# platform_designer_hps_system_hps_0_hps register map
Vendor: default_vendor.com; File version: 0.0
Registers are 32-bit, read-write, reset 0x0 unless marked. A register's access mark holds for its fields unless they carry their own. Offsets are from the block's base; [hi:lo] are bit positions; lines under a group give offsets from that group; {n}, {i} and the like mark numbered series.

## emac0 (part 2 of 5) — Registers in the EMAC module.
Base 0xFF700000
Same registers: emac1 0xFF702000
0x44 gmacgrp_MAC_Address0_Low reset 0xFFFFFFFF — The MAC Address0 Low register holds the lower 32 bits of the first 6-byte MAC address of the station.
  [31:0] addrlo — This field contains the lower 32 bits of the first 6-byte MAC address. This is used by the MAC for filtering the received frames and inserting the MAC address in the Transmit Flow Control (PAUSE) Frames.
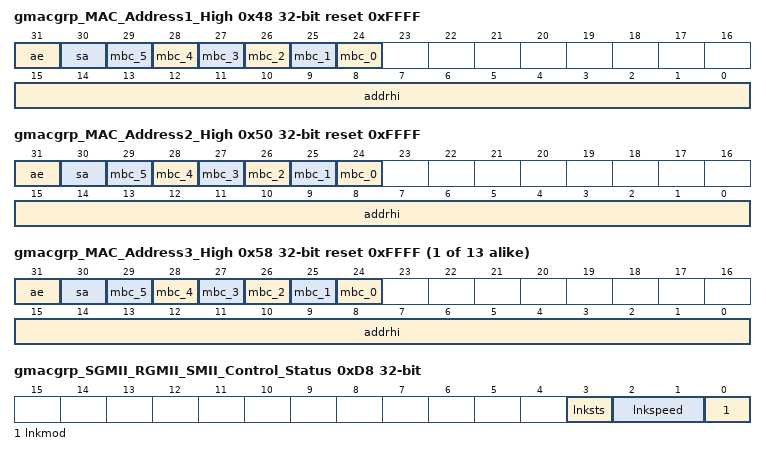
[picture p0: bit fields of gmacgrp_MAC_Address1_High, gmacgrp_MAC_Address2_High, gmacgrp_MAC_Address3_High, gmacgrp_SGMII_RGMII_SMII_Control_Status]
0x48 gmacgrp_MAC_Address1_High reset 0xFFFF — The MAC Address1 High register holds the upper 16 bits of the 2nd 6-byte MAC address of the station. Because the MAC address registers are configured to be double-synchronized to the (G)MII clock domains, the synchronization is triggered only when bits[31:24] (in little-endian mode) or Bits[7:0] (in big-endian mode) of the MAC Address1 Low Register are written. For proper synchronization updates, the consecutive writes to this Address Low Register should be performed after at least four clock cycles in the destination clock domain. Note that all MAC Address High registers (except MAC Address0 High) have the same format.
  [31] ae — When this bit is enabled, the address filter block uses the 2nd MAC address for perfect filtering. When this bit is disabled, the address filter block ignores the address for filtering.
    0=disabled; 1=enabled
  [30] sa — When this bit is enabled, the MAC Address1[47:0] is used to compare with the SA fields of the received frame. When this bit is disabled, the MAC Address1[47:0] is used to compare with the DA fields of the received frame.
    0=disabled; 1=enabled
  [n+24] mbc_{n} (n=0..5) — This array of bits are mask control bits for comparison of each of the MAC Address bytes. When masked, the MAC does not compare the corresponding byte of received DA or SA with the contents of MAC Address1 high and low registers. Each bit controls the masking of the bytes. You can filter a group of addresses (known as group address filtering) by masking one or more bytes of the address. The array index corresponds to the byte (e.g. index 0 is for bits 7:0).
    0=unmasked; 1=masked
  [15:0] addrhi — This field contains the upper 16 bits (47:32) of the 2nd 6-byte MAC address.
0x4C gmacgrp_MAC_Address1_Low reset 0xFFFFFFFF — The MAC Address1 Low register holds the lower 32 bits of the 2nd 6-byte MAC address of the station. Note that all MAC Address Low registers (except MAC Address0 Low) have the same format.
  [31:0] addrlo — This field contains the lower 32 bits of the 2nd 6-byte MAC address. The content of this field is undefined until loaded by software after the initialization process.
0x50 gmacgrp_MAC_Address2_High reset 0xFFFF — The MAC Address2 High register holds the upper 16 bits of the 3rd 6-byte MAC address of the station. Because the MAC address registers are configured to be double-synchronized to the (G)MII clock domains, the synchronization is triggered only when bits[31:24] (in little-endian mode) or Bits[7:0] (in big-endian mode) of the MAC Address2 Low Register are written. For proper synchronization updates, the consecutive writes to this Address Low Register should be performed after at least four clock cycles in the destination clock domain. Note that all MAC Address High registers (except MAC Address0 High) have the same format.
  [31] ae — When this bit is enabled, the address filter block uses the 3rd MAC address for perfect filtering. When this bit is disabled, the address filter block ignores the address for filtering.
    0=disabled; 1=enabled
  [30] sa — When this bit is enabled, the MAC Address2[47:0] is used to compare with the SA fields of the received frame. When this bit is disabled, the MAC Address2[47:0] is used to compare with the DA fields of the received frame.
    0=disabled; 1=enabled
  [n+24] mbc_{n} (n=0..5) — This array of bits are mask control bits for comparison of each of the MAC Address bytes. When masked, the MAC does not compare the corresponding byte of received DA or SA with the contents of MAC Address2 high and low registers. Each bit controls the masking of the bytes. You can filter a group of addresses (known as group address filtering) by masking one or more bytes of the address. The array index corresponds to the byte (e.g. index 0 is for bits 7:0).
    0=unmasked; 1=masked
  [15:0] addrhi — This field contains the upper 16 bits (47:32) of the 3rd 6-byte MAC address.
0x54 gmacgrp_MAC_Address2_Low reset 0xFFFFFFFF — The MAC Address2 Low register holds the lower 32 bits of the 3rd 6-byte MAC address of the station. Note that all MAC Address Low registers (except MAC Address0 Low) have the same format.
  [31:0] addrlo — This field contains the lower 32 bits of the 3rd 6-byte MAC address. The content of this field is undefined until loaded by software after the initialization process.
{0x40+8i} gmacgrp_MAC_Address{i}_High reset 0xFFFF (i=3..15) — The MAC Address{i} High register holds the upper 16 bits of the {i+1}th 6-byte MAC address of the station. Because the MAC address registers are configured to be double-synchronized to the (G)MII clock domains, the synchronization is triggered only when bits[31:24] (in little-endian mode) or Bits[7:0] (in big-endian mode) of the MAC Address{i} Low Register are written. For proper synchronization updates, the consecutive writes to this Address Low Register should be performed after at least four clock cycles in the destination clock domain. Note that all MAC Address High registers (except MAC Address0 High) have the same format.
  [31] ae — When this bit is enabled, the address filter block uses the {i+1}th MAC address for perfect filtering. When this bit is disabled, the address filter block ignores the address for filtering.
    0=disabled; 1=enabled
  [30] sa — When this bit is enabled, the MAC Address{i}[47:0] is used to compare with the SA fields of the received frame. When this bit is disabled, the MAC Address{i}[47:0] is used to compare with the DA fields of the received frame.
    0=disabled; 1=enabled
  [n+24] mbc_{n} (n=0..5) — This array of bits are mask control bits for comparison of each of the MAC Address bytes. When masked, the MAC does not compare the corresponding byte of received DA or SA with the contents of MAC Address{i} high and low registers. Each bit controls the masking of the bytes. You can filter a group of addresses (known as group address filtering) by masking one or more bytes of the address. The array index corresponds to the byte (e.g. index 0 is for bits 7:0).
    0=unmasked; 1=masked
  [15:0] addrhi — This field contains the upper 16 bits (47:32) of the {i+1}th 6-byte MAC address.
{0x44+8i} gmacgrp_MAC_Address{i}_Low reset 0xFFFFFFFF (i=3..15) — The MAC Address{i} Low register holds the lower 32 bits of the {i+1}th 6-byte MAC address of the station. Note that all MAC Address Low registers (except MAC Address0 Low) have the same format.
  [31:0] addrlo — This field contains the lower 32 bits of the {i+1}th 6-byte MAC address. The content of this field is undefined until loaded by software after the initialization process.
0xD8 gmacgrp_SGMII_RGMII_SMII_Control_Status ro — The SGMII/RGMII/SMII Status register indicates the status signals received by the RGMII interface (selected at reset) from the PHY.
  [3] lnksts — This bit indicates whether the link is up (1'b1) or down (1'b0).
    0=linkdown; 1=linkup
  [2:1] lnkspeed — This bit indicates the current speed of the link. Bit 2 is reserved when the MAC is configured for the SMII PHY interface.
    0=speed2point5MHz; 1=speed25MHz; 2=speed125MHz
  [0] lnkmod — This bit indicates the current mode of operation of the link
    0=halfdup; 1=fulldup
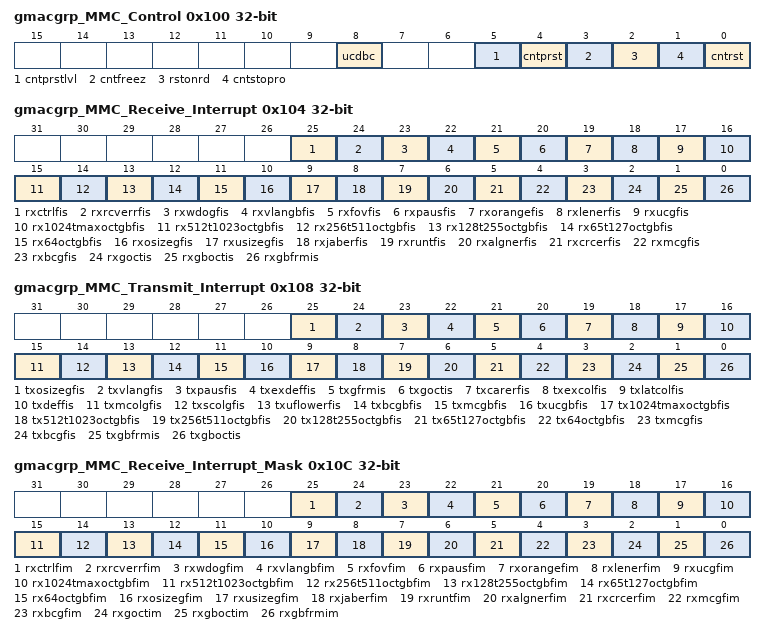
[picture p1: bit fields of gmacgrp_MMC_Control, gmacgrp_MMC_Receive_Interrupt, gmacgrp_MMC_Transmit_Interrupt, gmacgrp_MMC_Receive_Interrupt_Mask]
0x100 gmacgrp_MMC_Control — The MMC Control register establishes the operating mode of the management counters. Note: The bit 0 (Counters Reset) has higher priority than bit 4 (Counter Preset). Therefore, when the Software tries to set both bits in the same write cycle, all counters are cleared and the bit 4 is not set.
  [8] ucdbc — When set, this bit enables MAC to update all the related MMC Counters for Broadcast frames dropped due to setting of DBF bit (Disable Broadcast Frames) of MAC Filter Register at offset 0x0004. When reset, MMC Counters are not updated for dropped Broadcast frames.
  [5] cntprstlvl — When low and bit 4 is set, all MMC counters get preset to almost-half value. All octet counters get preset to 0x7FFF_F800 (half - 2KBytes) and all frame-counters gets preset to 0x7FFF_FFF0 (half - 16). When this bit is high and bit 4 is set, all MMC counters get preset to almost-full value. All octet counters get preset to 0xFFFF_F800 (full - 2KBytes) and all frame-counters gets preset to 0xFFFF_FFF0 (full - 16). For 16-bit counters, the almost-half preset values are 0x7800 and 0x7FF0 for the respective octet and frame counters. Similarly, the almost-full preset values for the 16-bit counters are 0xF800 and 0xFFF0.
    0=almosthalf; 1=almostfull
  [4] cntprst — When this bit is set, all counters are initialized or preset to almost full or almost half according to bit 5. This bit is cleared automatically after 1 clock cycle. This bit, along with bit 5, is useful for debugging and testing the assertion of interrupts because of MMC counter becoming half-full or full.
    0=disabled; 1=enabled
  [3] cntfreez — When this bit is set, it freezes all MMC counters to their current value. Until this bit is reset to 0, no MMC counter is updated because of any transmitted or received frame. If any MMC counter is read with the Reset on Read bit set, then that counter is also cleared in this mode.
    0=disabled; 1=enabled
  [2] rstonrd — When this bit is set, the MMC counters are reset to zero after Read (self-clearing after reset). The counters are cleared when the least significant byte lane (bits[7:0]) is read.
    0=disabled; 1=enabled
  [1] cntstopro — When this bit is set, after reaching maximum value, the counter does not roll over to zero.
    0=disabled; 1=enabled
  [0] cntrst — When this bit is set, all counters are reset. This bit is cleared automatically after one clock cycle.
    0=disabled; 1=enabled
0x104 gmacgrp_MMC_Receive_Interrupt ro — The MMC Receive Interrupt register maintains the interrupts that are generated when the following happens: * Receive statistic counters reach half of their maximum values (0x8000_0000 for 32-bit counter and 0x8000 for 16-bit counter). * Receive statistic counters cross their maximum values (0xFFFF_FFFF for 32-bit counter and 0xFFFF for 16-bit counter). When the Counter Stop Rollover is set, then interrupts are set but the counter remains at all-ones. The MMC Receive Interrupt register is a 32-bit wide register. An interrupt bit is cleared when the respective MMC counter that caused the interrupt is read. The least significant byte lane (Bits[7:0]) of the respective counter must be read in order to clear the interrupt bit.
  [25] rxctrlfis — This bit is set when the rxctrlframes_g counter reaches half of the maximum value or the maximum value.
  [24] rxrcverrfis — This bit is set when the rxrcverror counter reaches half of the maximum value or the maximum value.
  [23] rxwdogfis — This bit is set when the rxwatchdogerror counter reaches half of the maximum value or the maximum value.
    0=inactive; 1=active
  [22] rxvlangbfis — This bit is set when the rxvlanframes_gb counter reaches half of the maximum value or the maximum value.
    0=inactive; 1=active
  [21] rxfovfis — This bit is set when the rxfifooverflow counter reaches half of the maximum value or the maximum value.
    0=inactive; 1=active
  [20] rxpausfis — This bit is set when the rxpauseframe counter reaches half of the maximum value or the maximum value.
    0=inactive; 1=active
  [19] rxorangefis — This bit is set when the rxoutofrangetype counter reaches half of the maximum value or the maximum value.
    0=inactive; 1=active
  [18] rxlenerfis — This bit is set when the rxlengtherror counter reaches half of the maximum value or the maximum value.
    0=inactive; 1=active
  [17] rxucgfis — This bit is set when the rxunicastframes_gb counter reaches half of the maximum value or the maximum value.
    0=inactive; 1=active
  [16] rx1024tmaxoctgbfis — This bit is set when the rx1024tomaxoctets_gb counter reaches half of the maximum value or the maximum value.
    0=inactive; 1=active
  [15] rx512t1023octgbfis — This bit is set when the rx512to1023octets_gb counter reaches half of the maximum value or the maximum value.
    0=inactive; 1=active
  [14] rx256t511octgbfis — This bit is set when the rx256to511octets_gb counter reaches half of the maximum value or the maximum value.
    0=inactive; 1=active
  [13] rx128t255octgbfis — This bit is set when the rx128to255octets_gb counter reaches half of the maximum value or the maximum value.
    0=inactive; 1=active
  [12] rx65t127octgbfis — This is set when the rx65to127octets_gb counter reaches half of the maximum value or the maximum value.
    0=inactive; 1=active
  [11] rx64octgbfis — This bit is set when the rx64octets_gb counter reaches half of the maximum value or the maximum value.
    0=inactive; 1=active
  [10] rxosizegfis — This bit is set when the rxoversize_g counter reaches half of the maximum value or the maximum value.
    0=inactive; 1=active
  [9] rxusizegfis — This bit is set when the rxundersize_g counter reaches half of the maximum value or the maximum value.
    0=inactive; 1=active
  [8] rxjaberfis — This bit is set when the rxjabbererror counter reaches half of the maximum value or the maximum value.
    0=inactive; 1=active
  [7] rxruntfis — This bit is set when the rxrunterror counter reaches half of the maximum value or the maximum value.
    0=inactive; 1=active
  [6] rxalgnerfis — This bit is set when the rxalignmenterror counter reaches half of the maximum value or the maximum value.
    0=inactive; 1=active
  [5] rxcrcerfis — This bit is set when the rxcrcerror counter reaches half of the maximum value or the maximum value.
    0=inactive; 1=active
  [4] rxmcgfis — This bit is set when the rxmulticastframes_g counter reaches half of the maximum value or the maximum value.
    0=inactive; 1=active
  [3] rxbcgfis — This bit is set when the rxbroadcastframes_g counter reaches half of the maximum value or the maximum value.
  [2] rxgoctis — This bit is set when the rxoctetcount_g counter reaches half of the maximum value or the maximum value.
    0=inactive; 1=active
  [1] rxgboctis — This bit is set when the rxoctetcount_bg counter reaches half of the maximum value or the maximum value.
    0=inactive; 1=active
  [0] rxgbfrmis — This bit is set when the rxframecount_bg counter reaches half of the maximum value or the maximum value.
    0=almosthalf; 1=almostfull
0x108 gmacgrp_MMC_Transmit_Interrupt ro — The MMC Transmit Interrupt register maintains the interrupts generated when transmit statistic counters reach half of their maximum values (0x8000_0000 for 32-bit counter and 0x8000 for 16-bit counter), and the maximum values (0xFFFF_FFFF for 32-bit counter and 0xFFFF for 16-bit counter). When Counter Stop Rollover is set, then interrupts are set but the counter remains at all-ones. The MMC Transmit Interrupt register is a 32-bit wide register. An interrupt bit is cleared when the respective MMC counter that caused the interrupt is read. The least significant byte lane (Bits[7:0]) of the respective counter must be read in order to clear the interrupt bit.
  [25] txosizegfis — This bit is set when the txoversize_g counter reaches half of the maximum value or the maximum value.
  [24] txvlangfis — This bit is set when the txvlanframes_g counter reaches half of the maximum value or the maximum value.
    0=disabled; 1=enabled
  [23] txpausfis — This bit is set when the txpauseframeserror counter reaches half of the maximum value or the maximum value.
    0=disabled; 1=enabled
  [22] txexdeffis — This bit is set when the txexcessdef counter reaches half of the maximum value or the maximum value.
    0=disabled; 1=enabled
  [21] txgfrmis — This bit is set when the txframecount_g counter reaches half of the maximum value or the maximum value.
    0=disabled; 1=enabled
  [20] txgoctis — This bit is set when the txoctetcount_g counter reaches half of the maximum value or the maximum value.
    0=disabled; 1=enabled
  [19] txcarerfis — This bit is set when the txcarriererror counter reaches half of the maximum value or the maximum value.
    0=disabled; 1=enabled
  [18] txexcolfis — This bit is set when the txexcesscol counter reaches half of the maximum value or the maximum value.
    0=disabled; 1=enabled
  [17] txlatcolfis — This bit is set when the txlatecol counter reaches half of the maximum value or the maximum value.
    0=disabled; 1=enabled
  [16] txdeffis — This bit is set when the txdeferred counter reaches half of the maximum value or the maximum value.
    0=disabled; 1=enabled
  [15] txmcolgfis — This bit is set when the txmulticol_g counter reaches half of the maximum value or the maximum value.
    0=disabled; 1=enabled
  [14] txscolgfis — This bit is set when the txsinglecol_g counter reaches half of the maximum value or the maximum value.
    0=disabled; 1=enabled
  [13] txuflowerfis — This bit is set when the txunderflowerror counter reaches half of the maximum value or the maximum value.
    0=disabled; 1=enabled
  [12] txbcgbfis — This bit is set when the txbroadcastframes_gb counter reaches half of the maximum value or the maximum value.
    0=disabled; 1=enabled
  [11] txmcgbfis — This bit is set when the txmulticastframes_gb counter reaches half of the maximum value or the maximum value.
    0=inactive; 1=active
  [10] txucgbfis — This bit is set when the txunicastframes_gb counter reaches half of the maximum value or the maximum value.
    0=inactive; 1=active
  [9] tx1024tmaxoctgbfis — This bit is set when the tx1024tomaxoctets_gb counter reaches half of the maximum value or the maximum value.
    0=inactive; 1=active
  [8] tx512t1023octgbfis — This bit is set when the tx512to1023octets_gb counter reaches half of the maximum value or the maximum value.
    0=inactive; 1=active
  [7] tx256t511octgbfis — This bit is set when the tx256to511octets_gb counter reaches half of the maximum value or the maximum value.
    0=inactive; 1=active
  [6] tx128t255octgbfis — This bit is set when the tx128to255octets_gb counter reaches half of the maximum value or the maximum value.
    0=inactive; 1=active
  [5] tx65t127octgbfis — This bit is set when the tx65to127octets_gb counter reaches half of the maximum value or the maximum value.
    0=inactive; 1=active
  [4] tx64octgbfis — This bit is set when the tx64octets_gb counter reaches half of the maximum value or the maximum value.
    0=disabled; 1=enabled
  [3] txmcgfis — This bit is set when the txmulticastframes_g counter reaches half of the maximum value or the maximum value.
    0=inactive; 1=active
  [2] txbcgfis — This bit is set when the txbroadcastframes_g counter reaches half of the maximum value or the maximum value.
    0=inactive; 1=active
  [1] txgbfrmis — This bit is set when the txframecount_gb counter reaches half of the maximum value or the maximum value.
    0=inactive; 1=active
  [0] txgboctis — This bit is set when the txoctetcount_gb counter reaches half of the maximum value or the maximum value.
    0=inactive; 1=active
0x10C gmacgrp_MMC_Receive_Interrupt_Mask — The MMC Receive Interrupt Mask register maintains the masks for the interrupts generated when the receive statistic counters reach half of their maximum value, or maximum value. This register is 32-bits wide.
  [all] fields
    0=nomaskintr; 1=maskintr
  [25] rxctrlfim — Setting this bit masks the interrupt when the rxctrlframes counter reaches half the maximum value, and also when it reaches the maximum value.
  [24] rxrcverrfim — Setting this bit masks the interrupt when the rxrcverror error counter reaches half the maximum value, and also when it reaches the maximum value.
  [23] rxwdogfim — Setting this bit masks the interrupt when the rxwatchdog counter reaches half of the maximum value or the maximum value.
  [22] rxvlangbfim — Setting this bit masks the interrupt when the rxvlanframes_gb counter reaches half of the maximum value or the maximum value.
  [21] rxfovfim — Setting this bit masks the interrupt when the rxfifooverflow counter reaches half of the maximum value or the maximum value.
  [20] rxpausfim — Setting this bit masks the interrupt when the rxpauseframes counter reaches half of the maximum value or the maximum value.
  [19] rxorangefim — Setting this bit masks the interrupt when the rxoutofrangetype counter reaches half of the maximum value or the maximum value.
  [18] rxlenerfim — Setting this bit masks the interrupt when the rxlengtherror counter reaches half of the maximum value or the maximum value.
  [17] rxucgfim — Setting this bit masks the interrupt when the rxunicastframes_g counter reaches half of the maximum value or the maximum value.
  [16] rx1024tmaxoctgbfim — Setting this bit masks the interrupt when the rx1024tomaxoctets_gb counter reaches half of the maximum value or the maximum value.
  [15] rx512t1023octgbfim — Setting this bit masks the interrupt when the rx512to1023octets_gb counter reaches half of the maximum value or the maximum value.
  [14] rx256t511octgbfim — Setting this bit masks the interrupt when the rx256to511octets_gb counter reaches half of the maximum value or the maximum value.
  [13] rx128t255octgbfim — Setting this bit masks the interrupt when the rx128to255octets_gb counter reaches half of the maximum value or the maximum value.
  [12] rx65t127octgbfim — Setting this bit masks the interrupt when the rx65to127octets_gb counter reaches half of the maximum value or the maximum value.
  [11] rx64octgbfim — Setting this bit masks the interrupt when the rx64octets_gb counter reaches half of the maximum value or the maximum value.
  [10] rxosizegfim — Setting this bit masks the interrupt when the rxoversize_g counter reaches half of the maximum value or the maximum value.
  [9] rxusizegfim — Setting this bit masks the interrupt when the rxundersize_g counter reaches half of the maximum value or the maximum value.
  [8] rxjaberfim — Setting this bit masks the interrupt when the rxjabbererror counter reaches half of the maximum value or the maximum value.
  [7] rxruntfim — Setting this bit masks the interrupt when the rxrunterror counter reaches half of the maximum value or the maximum value.
  [6] rxalgnerfim — Setting this bit masks the interrupt when the rxalignmenterror counter reaches half of the maximum value or the maximum value.
  [5] rxcrcerfim — Setting this bit masks the interrupt when the rxcrcerror counter reaches half of the maximum value or the maximum value.
  [4] rxmcgfim — Setting this bit masks the interrupt when the rxmulticastframes_g counter reaches half of the maximum value or the maximum value.
  [3] rxbcgfim — Setting this bit masks the interrupt when the rxbroadcastframes_g counter reaches half of the maximum value or the maximum value.
  [2] rxgoctim — Setting this bit masks the interrupt when the rxoctetcount_g counter reaches half of the maximum value or the maximum value.
  [1] rxgboctim — Setting this bit masks the interrupt when the rxoctetcount_gb counter reaches half of the maximum value or the maximum value.
  [0] rxgbfrmim — Setting this bit masks the interrupt when the rxframecount_gb counter reaches half of the maximum value or the maximum value.
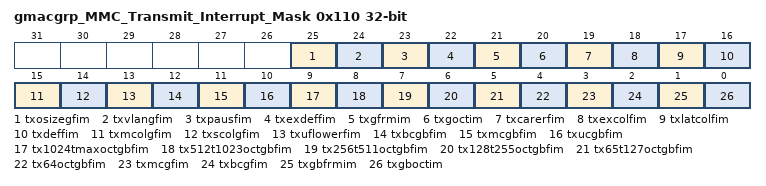
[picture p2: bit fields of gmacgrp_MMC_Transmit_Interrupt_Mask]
0x110 gmacgrp_MMC_Transmit_Interrupt_Mask — The MMC Transmit Interrupt Mask register maintains the masks for the interrupts generated when the transmit statistic counters reach half of their maximum value or maximum value. This register is 32-bits wide.
  [all] fields
    0=nomaskintr; 1=maskintr
  [25] txosizegfim — Setting this bit masks the interrupt when the txoversize_g counter reaches half of the maximum value or the maximum value.
  [24] txvlangfim — Setting this bit masks the interrupt when the txvlanframes_g counter reaches half of the maximum value or the maximum value.
  [23] txpausfim — Setting this bit masks the interrupt when the txpauseframes counter reaches half of the maximum value or the maximum value.
  [22] txexdeffim — Setting this bit masks the interrupt when the txexcessdef counter reaches half of the maximum value or the maximum value.
  [21] txgfrmim — Setting this bit masks the interrupt when the txframecount_g counter reaches half of the maximum value or the maximum value.
  [20] txgoctim — Setting this bit masks the interrupt when the txoctetcount_g counter reaches half of the maximum value or the maximum value.
  [19] txcarerfim — Setting this bit masks the interrupt when the txcarriererror counter reaches half of the maximum value or the maximum value.
  [18] txexcolfim — Setting this bit masks the interrupt when the txexcesscol counter reaches half of the maximum value or the maximum value.
  [17] txlatcolfim — Setting this bit masks the interrupt when the txlatecol counter reaches half of the maximum value or the maximum value.
  [16] txdeffim — Setting this bit masks the interrupt when the txdeferred counter reaches half of the maximum value or the maximum value.
  [15] txmcolgfim — Setting this bit masks the interrupt when the txmulticol_g counter reaches half of the maximum value or the maximum value.
  [14] txscolgfim — Setting this bit masks the interrupt when the txsinglecol_g counter reaches half of the maximum value or the maximum value.
  [13] txuflowerfim — Setting this bit masks the interrupt when the txunderflowerror counter reaches half of the maximum value or the maximum value.
  [12] txbcgbfim — Setting this bit masks the interrupt when the txbroadcastframes_gb counter reaches half of the maximum value or the maximum value.
  [11] txmcgbfim — Setting this bit masks the interrupt when the txmulticastframes_gb counter reaches half of the maximum value or the maximum value.
  [10] txucgbfim — Setting this bit masks the interrupt when the txunicastframes_gb counter reaches half of the maximum value or the maximum value.
  [9] tx1024tmaxoctgbfim — Setting this bit masks the interrupt when the tx1024tomaxoctets_gb counter reaches half of the maximum value or the maximum value.
  [8] tx512t1023octgbfim — Setting this bit masks the interrupt when the tx512to1023octets_gb counter reaches half of the maximum value or the maximum value.
  [7] tx256t511octgbfim — Setting this bit masks the interrupt when the tx256to511octets_gb counter reaches half of the maximum value or the maximum value.
  [6] tx128t255octgbfim — Setting this bit masks the interrupt when the tx128to255octets_gb counter reaches half of the maximum value or the maximum value.
  [5] tx65t127octgbfim — Setting this bit masks the interrupt when the tx65to127octets_gb counter reaches half of the maximum value or the maximum value.
  [4] tx64octgbfim — Setting this bit masks the interrupt when the tx64octets_gb counter reaches half of the maximum value or the maximum value.
  [3] txmcgfim — Setting this bit masks the interrupt when the txmulticastframes_g counter reaches half of the maximum value or the maximum value.
  [2] txbcgfim — Setting this bit masks the interrupt when the txbroadcastframes_g counter reaches half of the maximum value or the maximum value.
  [1] txgbfrmim — Setting this bit masks the interrupt when the txframecount_gb counter reaches half of the maximum value or the maximum value.
  [0] txgboctim — Setting this bit masks the interrupt when the txoctetcount_gb counter reaches half of the maximum value or the maximum value.
0x114 gmacgrp_txoctetcount_gb ro — Number of bytes transmitted, exclusive of preamble and retried bytes, in good and bad frames
  [31:0] cnt
0x118 gmacgrp_txframecount_gb ro — Number of good and bad frames transmitted, exclusive of retried frames
  [31:0] cnt
0x11C gmacgrp_txbroadcastframes_g ro — Number of good broadcast frames transmitted
  [31:0] cnt
0x120 gmacgrp_txmulticastframes_g ro — Number of good multicast frames transmitted
  [31:0] cnt
0x124 gmacgrp_tx64octets_gb ro — Number of good and bad frames transmitted with length 64 bytes, exclusive of preamble and retried frames
  [31:0] cnt
0x128 gmacgrp_tx65to127octets_gb ro — Number of good and bad frames transmitted with length between 65 and 127 (inclusive) bytes, exclusive of preamble and retried frames
  [31:0] cnt
0x12C gmacgrp_tx128to255octets_gb ro — Number of good and bad frames transmitted with length between 128 and 255 (inclusive) bytes, exclusive of preamble and retried frames
  [31:0] cnt
0x130 gmacgrp_tx256to511octets_gb ro — Number of good and bad frames transmitted with length between 256 and 511 (inclusive) bytes, exclusive of preamble and retried frames
  [31:0] cnt
0x134 gmacgrp_tx512to1023octets_gb ro — Number of good and bad frames transmitted with length between 512 and 1,023 (inclusive) bytes, exclusive of preamble and retried frames
  [31:0] cnt
0x138 gmacgrp_tx1024tomaxoctets_gb ro — Number of good and bad frames transmitted with length between 1,024 and maxsize (inclusive) bytes, exclusive of preamble and retried frames
  [31:0] cnt
0x13C gmacgrp_txunicastframes_gb ro — Number of good and bad unicast frames transmitted
  [31:0] cnt
0x140 gmacgrp_txmulticastframes_gb ro — Number of good and bad multicast frames transmitted
  [31:0] cnt
0x144 gmacgrp_txbroadcastframes_gb ro — Number of good and bad broadcast frames transmitted
  [31:0] cnt
0x148 gmacgrp_txunderflowerror ro — Number of frames aborted due to frame underflow error
  [31:0] cnt
0x14C gmacgrp_txsinglecol_g ro — Number of successfully transmitted frames after a single collision in Half-duplex mode
  [31:0] cnt
0x150 gmacgrp_txmulticol_g ro — Number of successfully transmitted frames after more than a single collision in Half-duplex mode
  [31:0] cnt
0x154 gmacgrp_txdeferred ro — Number of successfully transmitted frames after a deferral in Halfduplex mode
  [31:0] cnt
0x158 gmacgrp_txlatecol ro — Number of frames aborted due to late collision error
  [31:0] cnt
0x15C gmacgrp_txexesscol ro — Number of frames aborted due to excessive (16) collision errors
  [31:0] cnt
0x160 gmacgrp_txcarriererr ro — Number of frames aborted due to carrier sense error (no carrier or loss of carrier)
  [31:0] cnt
0x164 gmacgrp_txoctetcnt ro — Number of bytes transmitted, exclusive of preamble, in good frames only
  [31:0] txoctetcount_g
0x168 gmacgrp_txframecount_g ro — Number of good frames transmitted
  [31:0] cnt
0x16C gmacgrp_txexcessdef ro — Number of frames aborted due to excessive deferral error (deferred for more than two max-sized frame times)
  [31:0] cnt
0x170 gmacgrp_txpauseframes ro — Number of good PAUSE frames transmitted
  [31:0] cnt
0x174 gmacgrp_txvlanframes_g ro — Number of good VLAN frames transmitted, exclusive of retried frames
  [31:0] cnt
0x178 gmacgrp_txoversize_g ro — Number of good and bad frames received
  [31:0] cnt
0x180 gmacgrp_rxframecount_gb ro — Number of good and bad frames received
  [31:0] cnt
0x184 gmacgrp_rxoctetcount_gb ro — Number of bytes received, exclusive of preamble, in good and bad frames
  [31:0] cnt
0x188 gmacgrp_rxoctetcount_g ro — Number of bytes received, exclusive of preamble, only in good frames
  [31:0] cnt
0x18C gmacgrp_rxbroadcastframes_g ro — Number of good broadcast frames received
  [31:0] cnt
0x190 gmacgrp_rxmulticastframes_g ro — Number of good multicast frames received
  [31:0] cnt
0x194 gmacgrp_rxcrcerror ro — Number of frames received with CRC error
  [31:0] cnt
0x198 gmacgrp_rxalignmenterror ro — Number of frames received with alignment (dribble) error. Valid only in 10/100 mode
  [31:0] cnt
0x19C gmacgrp_rxrunterror ro — Number of frames received with runt (<64 bytes and CRC error) error
  [31:0] cnt
0x1A0 gmacgrp_rxjabbererror ro — Number of giant frames received with length (including CRC) greater than 1,518 bytes (1,522 bytes for VLAN tagged) and with CRC error. If Jumbo Frame mode is enabled, then frames of length greater than 9,018 bytes (9,022 for VLAN tagged) are considered as giant frames
  [31:0] cnt
0x1A4 gmacgrp_rxundersize_g ro — Number of frames received with length less than 64 bytes, without any errors
  [31:0] cnt
0x1A8 gmacgrp_rxoversize_g ro — Number of frames received with length greater than the maxsize (1,518 or 1,522 for VLAN tagged frames), without errors
  [31:0] cnt
0x1AC gmacgrp_rx64octets_gb ro — Number of good and bad frames received with length 64 bytes, exclusive of preamble
  [31:0] cnt
0x1B0 gmacgrp_rx65to127octets_gb ro — Number of good and bad frames received with length between 65 and 127 (inclusive) bytes, exclusive of preamble
  [31:0] cnt
0x1B4 gmacgrp_rx128to255octets_gb ro — Number of good and bad frames received with length between 128 and 255 (inclusive) bytes, exclusive of preamble
  [31:0] cnt
0x1B8 gmacgrp_rx256to511octets_gb ro — Number of good and bad frames received with length between 256 and 511 (inclusive) bytes, exclusive of preamble
  [31:0] cnt
0x1BC gmacgrp_rx512to1023octets_gb ro — Number of good and bad frames received with length between 512 and 1,023 (inclusive) bytes, exclusive of preamble
  [31:0] cnt
0x1C0 gmacgrp_rx1024tomaxoctets_gb ro — Number of good and bad frames received with length between 1,024 and maxsize (inclusive) bytes, exclusive of preamble and retried frames
  [31:0] cnt
0x1C4 gmacgrp_rxunicastframes_g ro — Number of good unicast frames received
  [31:0] cnt
0x1C8 gmacgrp_rxlengtherror ro — Number of frames received with length error (length type field not equal to frame size), for all frames with valid length field
  [31:0] cnt
0x1CC gmacgrp_rxoutofrangetype ro — Number of frames received with length field not equal to the valid frame size (greater than 1,500 but less than 1,536)
  [31:0] cnt
0x1D0 gmacgrp_rxpauseframes ro — Number of good and valid PAUSE frames received
  [31:0] cnt
0x1D4 gmacgrp_rxfifooverflow ro — Number of missed received frames due to FIFO overflow
  [31:0] cnt
0x1D8 gmacgrp_rxvlanframes_gb ro — Number of good and bad VLAN frames received
  [31:0] cnt
0x1DC gmacgrp_rxwatchdogerror ro — Number of frames received with error due to watchdog timeout error (frames with a data load larger than 2,048 bytes)
  [31:0] cnt
0x1E0 gmacgrp_rxrcverror ro — Number of frames received with Receive error or Frame Extension error on the GMII or MII interface.
  [31:0] cnt
0x1E4 gmacgrp_rxctrlframes_g ro — Number of received good control frames.
  [31:0] cnt
